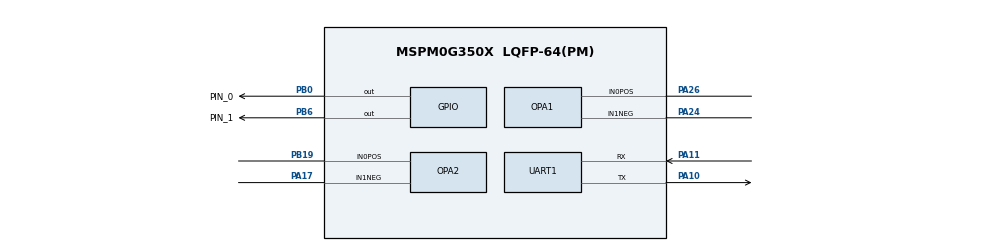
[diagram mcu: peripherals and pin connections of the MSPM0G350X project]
/**
 * These arguments were used when this file was generated. They will be automatically applied on subsequent loads
 * via the GUI or CLI. Run CLI with '--help' for additional information on how to override these arguments.
 * @cliArgs --device "MSPM0G350X" --package "LQFP-64(PM)" --part "Default" --product "mspm0_sdk@2.01.00.03"
 * @versions {"tool":"1.20.0+3587"}
 */

/**
 * Import the modules used in this configuration.
 */
const ADC12         = scripting.addModule("/ti/driverlib/ADC12", {}, false);
const ADC121        = ADC12.addInstance();
const ADC122        = ADC12.addInstance();
const COMP          = scripting.addModule("/ti/driverlib/COMP", {}, false);
const COMP1         = COMP.addInstance();
const GPIO          = scripting.addModule("/ti/driverlib/GPIO", {}, false);
const GPIO1         = GPIO.addInstance();
const GPIO2         = GPIO.addInstance();
const OPA           = scripting.addModule("/ti/driverlib/OPA", {}, false);
const OPA1          = OPA.addInstance();
const OPA2          = OPA.addInstance();
const SPI           = scripting.addModule("/ti/driverlib/SPI", {}, false);
const SPI1          = SPI.addInstance();
const SYSCTL        = scripting.addModule("/ti/driverlib/SYSCTL");
const TIMER         = scripting.addModule("/ti/driverlib/TIMER", {}, false);
const TIMER1        = TIMER.addInstance();
const UART          = scripting.addModule("/ti/driverlib/UART", {}, false);
const UART1         = UART.addInstance();
const ProjectConfig = scripting.addModule("/ti/project_config/ProjectConfig");

/**
 * Write custom configuration values to the imported modules.
 */
const divider6       = system.clockTree["PLL_CLK2X_DIV"];
divider6.divideValue = 8;

const multiplier2         = system.clockTree["PLL_QDIV"];
multiplier2.multiplyValue = 4;

const mux4       = system.clockTree["EXHFMUX"];
mux4.inputSelect = "EXHFMUX_XTAL";

const mux8       = system.clockTree["HSCLKMUX"];
mux8.inputSelect = "HSCLKMUX_SYSPLL2X";

const mux12       = system.clockTree["SYSPLLMUX"];
mux12.inputSelect = "zSYSPLLMUX_HFCLK";

const pinFunction4        = system.clockTree["HFXT"];
pinFunction4.inputFreq    = 40;
pinFunction4.enable       = true;
pinFunction4.HFXTStartup  = 20;
pinFunction4.HFCLKMonitor = true;

ADC121.$name                             = "ADC12_0";
ADC121.sampClkSrc                        = "DL_ADC12_CLOCK_ULPCLK";
ADC121.repeatMode                        = true;
ADC121.trigSrc                           = "DL_ADC12_TRIG_SRC_EVENT";
ADC121.adcMem0trig                       = "DL_ADC12_TRIGGER_MODE_TRIGGER_NEXT";
ADC121.powerDownMode                     = "DL_ADC12_POWER_DOWN_MODE_MANUAL";
ADC121.enabledInterrupts                 = ["DL_ADC12_INTERRUPT_DMA_DONE"];
ADC121.configureDMA                      = true;
ADC121.sampCnt                           = 1;
ADC121.enabledDMATriggers                = ["DL_ADC12_DMA_MEM0_RESULT_LOADED"];
ADC121.subChanID                         = 12;
ADC121.sampleTime0                       = "20 us";
ADC121.adcMem0chansel                    = "DL_ADC12_INPUT_CHAN_13";
ADC121.peripheral.$assign                = "ADC0";
ADC121.DMA_CHANNEL.$name                 = "DMA_CH0";
ADC121.DMA_CHANNEL.addressMode           = "f2b";
ADC121.DMA_CHANNEL.srcLength             = "HALF_WORD";
ADC121.DMA_CHANNEL.dstLength             = "HALF_WORD";
ADC121.DMA_CHANNEL.configureTransferSize = true;
ADC121.DMA_CHANNEL.transferMode          = "FULL_CH_REPEAT_SINGLE";
ADC121.DMA_CHANNEL.transferSize          = 1024;
ADC121.DMA_CHANNEL.peripheral.$assign    = "DMA_CH0";

ADC122.$name                             = "ADC12_1";
ADC122.sampClkSrc                        = "DL_ADC12_CLOCK_ULPCLK";
ADC122.repeatMode                        = true;
ADC122.trigSrc                           = "DL_ADC12_TRIG_SRC_EVENT";
ADC122.powerDownMode                     = "DL_ADC12_POWER_DOWN_MODE_MANUAL";
ADC122.configureDMA                      = true;
ADC122.sampCnt                           = 1;
ADC122.enabledDMATriggers                = ["DL_ADC12_DMA_MEM0_RESULT_LOADED"];
ADC122.subChanID                         = 12;
ADC122.sampleTime0                       = "20 us";
ADC122.adcMem0trig                       = "DL_ADC12_TRIGGER_MODE_TRIGGER_NEXT";
ADC122.adcMem0chansel                    = "DL_ADC12_INPUT_CHAN_13";
ADC122.DMA_CHANNEL.$name                 = "DMA_CH1";
ADC122.DMA_CHANNEL.addressMode           = "f2b";
ADC122.DMA_CHANNEL.srcLength             = "HALF_WORD";
ADC122.DMA_CHANNEL.dstLength             = "HALF_WORD";
ADC122.DMA_CHANNEL.configureTransferSize = true;
ADC122.DMA_CHANNEL.transferMode          = "FULL_CH_REPEAT_SINGLE";
ADC122.DMA_CHANNEL.transferSize          = 1024;

const Board = scripting.addModule("/ti/driverlib/Board", {}, false);

COMP1.$name              = "COMP_0";
COMP1.hysteresis         = "DL_COMP_HYSTERESIS_20";
COMP1.vSource            = "DL_COMP_REF_SOURCE_VDDA_DAC";
COMP1.terminalSelect     = "DL_COMP_REF_TERMINAL_SELECT_NEG";
COMP1.controlSelect      = "DL_COMP_DAC_CONTROL_SW";
COMP1.setDACCode0        = 0x80;
COMP1.channelEnable      = ["POS"];
COMP1.posChannel         = "DL_COMP_IPSEL_CHANNEL_6";
COMP1.enableOutputFilter = true;
COMP1.enabledInterrupts  = ["DL_COMP_INTERRUPT_OUTPUT_EDGE","DL_COMP_INTERRUPT_OUTPUT_EDGE_INV"];
COMP1.selectOutputFilter = "DL_COMP_FILTER_DELAY_2700";
COMP1.peripheral.$assign = "COMP0";

GPIO1.$name                              = "GPIO_SWITCHES";
GPIO1.port                               = "PORTB";
GPIO1.associatedPins[0].$name            = "USER_SWITCH_1";
GPIO1.associatedPins[0].direction        = "INPUT";
GPIO1.associatedPins[0].assignedPin      = "21";
GPIO1.associatedPins[0].internalResistor = "PULL_UP";

GPIO2.$name                         = "GPIO_GAIN_SW";
GPIO2.port                          = "PORTB";
GPIO2.associatedPins.create(2);
GPIO2.associatedPins[0].$name       = "PIN_0";
GPIO2.associatedPins[0].pin.$assign = "PB0";
GPIO2.associatedPins[1].$name       = "PIN_1";
GPIO2.associatedPins[1].pin.$assign = "PB6";

OPA1.$name                        = "OPA_0";
OPA1.cfg0PSELChannel              = "IN0_POS";
OPA1.cfg0NSELChannel              = "RTAP";
OPA1.cfg0Gain                     = "N1_P2";
OPA1.cfg0MSELChannel              = "IN1_NEG";
OPA1.advRRI                       = true;
OPA1.peripheral.$assign           = "OPA0";
OPA1.peripheral.In0PosPin.$assign = "PA26";
OPA1.peripheral.In1NegPin.$assign = "PA24";
OPA1.In0PosPinConfig.$name        = "ti_driverlib_gpio_GPIOPinGeneric0";
OPA1.In1NegPinConfig.$name        = "ti_driverlib_gpio_GPIOPinGeneric1";

OPA2.$name                        = "OPA_1";
OPA2.cfg0PSELChannel              = "IN0_POS";
OPA2.cfg0NSELChannel              = "RTAP";
OPA2.cfg0MSELChannel              = "IN1_NEG";
OPA2.advRRI                       = true;
OPA2.cfg0Gain                     = "N1_P2";
OPA2.peripheral.$assign           = "OPA1";
OPA2.peripheral.In0PosPin.$assign = "PB19";
OPA2.peripheral.In1NegPin.$assign = "PA17";
OPA2.In0PosPinConfig.$name        = "ti_driverlib_gpio_GPIOPinGeneric2";
OPA2.In1NegPinConfig.$name        = "ti_driverlib_gpio_GPIOPinGeneric3";

SPI1.$name               = "SPI_0";
SPI1.enableCDMode        = true;
SPI1.targetBitRate       = 500000;
SPI1.frameFormat         = "MOTO3";
SPI1.sclkPinConfig.$name = "ti_driverlib_gpio_GPIOPinGeneric4";
SPI1.mosiPinConfig.$name = "ti_driverlib_gpio_GPIOPinGeneric5";
SPI1.misoPinConfig.$name = "ti_driverlib_gpio_GPIOPinGeneric6";
SPI1.cs3PinConfig.$name  = "ti_driverlib_gpio_GPIOPinGeneric8";

SYSCTL.forceDefaultClkConfig = true;
SYSCTL.clockTreeEn           = true;

TIMER1.$name                       = "TIMER_0";
TIMER1.timerMode                   = "PERIODIC";
TIMER1.event1PublisherChannel      = 12;
TIMER1.event1ControllerInterruptEn = ["ZERO_EVENT"];
TIMER1.timerPeriod                 = "100 us";
TIMER1.interrupts                  = ["ZERO"];
TIMER1.peripheral.$assign          = "TIMG0";

UART1.$name                    = "UART_0";
UART1.targetBaudRate           = 115200;
UART1.peripheral.$assign       = "UART0";
UART1.peripheral.rxPin.$assign = "PA11";
UART1.peripheral.txPin.$assign = "PA10";
UART1.txPinConfig.$name        = "ti_driverlib_gpio_GPIOPinGeneric7";
UART1.rxPinConfig.$name        = "ti_driverlib_gpio_GPIOPinGeneric9";

ProjectConfig.genLibCMSIS = true;

/**
 * Pinmux solution for unlocked pins/peripherals. This ensures that minor changes to the automatic solver in a future
 * version of the tool will not impact the pinmux you originally saw.  These lines can be completely deleted in order to
 * re-solve from scratch.
 */
pinFunction4.peripheral.$suggestSolution           = "SYSCTL";
pinFunction4.peripheral.hfxInPin.$suggestSolution  = "PA5";
pinFunction4.peripheral.hfxOutPin.$suggestSolution = "PA6";
ADC122.peripheral.$suggestSolution                 = "ADC1";
ADC122.DMA_CHANNEL.peripheral.$suggestSolution     = "DMA_CH1";
Board.peripheral.$suggestSolution                  = "DEBUGSS";
Board.peripheral.swclkPin.$suggestSolution         = "PA20";
Board.peripheral.swdioPin.$suggestSolution         = "PA19";
GPIO1.associatedPins[0].pin.$suggestSolution       = "PB21";
SPI1.peripheral.$suggestSolution                   = "SPI0";
SPI1.peripheral.sclkPin.$suggestSolution           = "PA12";
SPI1.peripheral.mosiPin.$suggestSolution           = "PA14";
SPI1.peripheral.misoPin.$suggestSolution           = "PA13";
SPI1.peripheral.cs3Pin.$suggestSolution            = "PA23";
